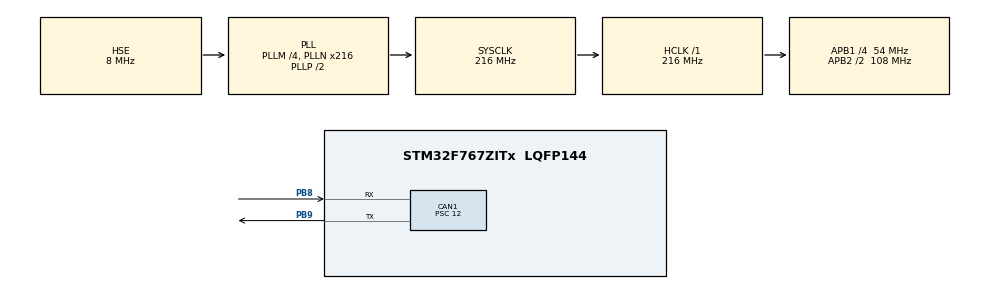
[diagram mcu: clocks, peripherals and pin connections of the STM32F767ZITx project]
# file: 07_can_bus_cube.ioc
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CAN1.BS1=CAN_BS1_15TQ
CAN1.BS2=CAN_BS2_2TQ
CAN1.CalculateBaudRate=250000
CAN1.CalculateTimeBit=4000
CAN1.CalculateTimeQuantum=222.22222222222223
CAN1.Mode=CAN_MODE_NORMAL
CAN1.Prescaler=12
CAN1.SJW=CAN_SJW_1TQ
Mcu.Family=STM32F7
Mcu.Name=STM32F767ZITx
Mcu.Package=LQFP144
NVIC.CAN1_RX0_IRQn=true\:0\:0\:false\:false\:true\:true\:true
NVIC.CAN1_RX1_IRQn=true\:0\:0\:false\:false\:true\:true\:true
NVIC.CAN1_SCE_IRQn=true\:0\:0\:false\:false\:true\:true\:true
NVIC.CAN1_TX_IRQn=true\:0\:0\:false\:false\:true\:true\:true
NVIC.PriorityGroup=NVIC_PRIORITYGROUP_4
NVIC.RCC_IRQn=true\:0\:0\:false\:false\:true\:true\:false
PB8.Mode=CAN_Activate
PB8.Signal=CAN1_RX
PB9.Mode=CAN_Activate
PB9.Signal=CAN1_TX
PH0/OSC_IN.Mode=HSE-External-Clock-Source
PH0/OSC_IN.Signal=RCC_OSC_IN
PH1/OSC_OUT.Mode=HSE-External-Clock-Source
PH1/OSC_OUT.Signal=RCC_OSC_OUT
ProjectManager.HeapSize=0x200
ProjectManager.StackSize=0x400
ProjectManager.TargetToolchain=STM32CubeIDE
RCC.AHBFreq_Value=216000000
RCC.APB1CLKDivider=RCC_HCLK_DIV4
RCC.APB1Freq_Value=54000000
RCC.APB1TimFreq_Value=108000000
RCC.APB2CLKDivider=RCC_HCLK_DIV2
RCC.APB2Freq_Value=108000000
RCC.APB2TimFreq_Value=216000000
RCC.CortexFreq_Value=216000000
RCC.EnbaleCSS=true
RCC.HCLKFreq_Value=216000000
RCC.HSE_VALUE=8000000
RCC.HSI_VALUE=16000000
RCC.LSE_VALUE=32768
RCC.PLLM=4
RCC.PLLN=216
RCC.PLLSourceVirtual=RCC_PLLSOURCE_HSE
RCC.SYSCLKFreq_VALUE=216000000
RCC.SYSCLKSource=RCC_SYSCLKSOURCE_PLLCLK
RCC.USBFreq_Value=216000000
RCC.VCOOutputFreq_Value=432000000
board=custom

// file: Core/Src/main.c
/* USER CODE BEGIN Header */
/**
  ******************************************************************************
  * @file           : main.c
  * @brief          : Main program body
  ******************************************************************************
  * @attention
  *
  * <h2><center>&copy; Copyright (c) 2021 STMicroelectronics.
  * All rights reserved.</center></h2>
  *
  * This software component is licensed by ST under BSD 3-Clause license,
  * the "License"; You may not use this file except in compliance with the
  * License. You may obtain a copy of the License at:
  *                        opensource.org/licenses/BSD-3-Clause
  *
  ******************************************************************************
  */
/* USER CODE END Header */
#include "main.h"

CAN_HandleTypeDef hcan1;

/* USER CODE BEGIN PV */

// TX and RX msg typedef

CAN_RxHeaderTypeDef RxHeader;
CAN_TxHeaderTypeDef TxHeader;

uint32_t err_counter = 0;
uint8_t TxData[8];
uint8_t RxData[8];

uint32_t TxMailBox;
uint32_t rx_counter =0;

/* USER CODE END PV */

void SystemClock_Config(void);
static void MX_GPIO_Init(void);
static void MX_CAN1_Init(void);
/* USER CODE BEGIN PFP */

void myCanFilterConfig(void);

/* USER CODE END PFP */

int main(void)
{

  /* MCU Configuration--------------------------------------------------------*/

  /* Reset of all peripherals, Initializes the Flash interface and the Systick. */
  HAL_Init();

  /* Configure the system clock */
  SystemClock_Config();

  /* Initialize all configured peripherals */
  MX_GPIO_Init();
  MX_CAN1_Init();
  /* USER CODE BEGIN 2 */

  HAL_CAN_Start(&hcan1);

  // Activate Notification

  HAL_CAN_ActivateNotification(&hcan1, CAN_IT_RX_FIFO0_MSG_PENDING);

  TxHeader.DLC = 1;
  TxHeader.IDE = CAN_ID_STD;
  TxHeader.RTR = CAN_RTR_DATA;

  TxHeader.StdId = 0x103;
  TxData[0] = 45;

  HAL_CAN_AddTxMessage(&hcan1, &TxHeader, TxData, &TxMailBox);

  /* USER CODE END 2 */

  /* Infinite loop */
  while (1)
  {

    /* USER CODE BEGIN 3 */
	  HAL_CAN_AddTxMessage(&hcan1, &TxHeader, TxData, &TxMailBox);
	  HAL_Delay(1000);
  }
  /* USER CODE END 3 */
}

void SystemClock_Config(void)
{
  RCC_OscInitTypeDef RCC_OscInitStruct = {0};
  RCC_ClkInitTypeDef RCC_ClkInitStruct = {0};

  /** Configure the main internal regulator output voltage
  */
  __HAL_RCC_PWR_CLK_ENABLE();
  __HAL_PWR_VOLTAGESCALING_CONFIG(PWR_REGULATOR_VOLTAGE_SCALE1);
  /** Initializes the RCC Oscillators according to the specified parameters
  * in the RCC_OscInitTypeDef structure.
  */
  RCC_OscInitStruct.OscillatorType = RCC_OSCILLATORTYPE_HSE;
  RCC_OscInitStruct.HSEState = RCC_HSE_BYPASS;
  RCC_OscInitStruct.PLL.PLLState = RCC_PLL_ON;
  RCC_OscInitStruct.PLL.PLLSource = RCC_PLLSOURCE_HSE;
  RCC_OscInitStruct.PLL.PLLM = 4;
  RCC_OscInitStruct.PLL.PLLN = 216;
  RCC_OscInitStruct.PLL.PLLP = RCC_PLLP_DIV2;
  RCC_OscInitStruct.PLL.PLLQ = 2;
  RCC_OscInitStruct.PLL.PLLR = 2;
  if (HAL_RCC_OscConfig(&RCC_OscInitStruct) != HAL_OK)
  {
    Error_Handler();
  }
  /** Activate the Over-Drive mode
  */
  if (HAL_PWREx_EnableOverDrive() != HAL_OK)
  {
    Error_Handler();
  }
  /** Initializes the CPU, AHB and APB buses clocks
  */
  RCC_ClkInitStruct.ClockType = RCC_CLOCKTYPE_HCLK|RCC_CLOCKTYPE_SYSCLK
                              |RCC_CLOCKTYPE_PCLK1|RCC_CLOCKTYPE_PCLK2;
  RCC_ClkInitStruct.SYSCLKSource = RCC_SYSCLKSOURCE_PLLCLK;
  RCC_ClkInitStruct.AHBCLKDivider = RCC_SYSCLK_DIV1;
  RCC_ClkInitStruct.APB1CLKDivider = RCC_HCLK_DIV4;
  RCC_ClkInitStruct.APB2CLKDivider = RCC_HCLK_DIV2;

  if (HAL_RCC_ClockConfig(&RCC_ClkInitStruct, FLASH_LATENCY_7) != HAL_OK)
  {
    Error_Handler();
  }
  /** Enables the Clock Security System
  */
  HAL_RCC_EnableCSS();
}

static void MX_CAN1_Init(void)
{

  hcan1.Instance = CAN1;
  hcan1.Init.Prescaler = 12;
  hcan1.Init.Mode = CAN_MODE_NORMAL;
  hcan1.Init.SyncJumpWidth = CAN_SJW_1TQ;
  hcan1.Init.TimeSeg1 = CAN_BS1_15TQ;
  hcan1.Init.TimeSeg2 = CAN_BS2_2TQ;
  hcan1.Init.TimeTriggeredMode = DISABLE;
  hcan1.Init.AutoBusOff = DISABLE;
  hcan1.Init.AutoWakeUp = DISABLE;
  hcan1.Init.AutoRetransmission = DISABLE;
  hcan1.Init.ReceiveFifoLocked = DISABLE;
  hcan1.Init.TransmitFifoPriority = DISABLE;
  if (HAL_CAN_Init(&hcan1) != HAL_OK)
  {
    Error_Handler();
  }
  /* USER CODE BEGIN CAN1_Init 2 */
  myCanFilterConfig();
  /* USER CODE END CAN1_Init 2 */

}

static void MX_GPIO_Init(void)
{

  /* GPIO Ports Clock Enable */
  __HAL_RCC_GPIOH_CLK_ENABLE();
  __HAL_RCC_GPIOB_CLK_ENABLE();

}

/* USER CODE BEGIN 4 */

void HAL_CAN_RxFifo0MsgPendingCallback(CAN_HandleTypeDef *hcan)
{

	HAL_CAN_GetRxMessage(&hcan1, CAN_RX_FIFO0, &RxHeader, RxData);
	rx_counter++;

}

void myCanFilterConfig(void){
	CAN_FilterTypeDef filterConfig;

	filterConfig.FilterBank = 13;
	filterConfig.FilterActivation = ENABLE;
	filterConfig.FilterFIFOAssignment = CAN_FILTER_FIFO0;
	filterConfig.FilterIdHigh = 0x0000;
	filterConfig.FilterIdLow = 0x0000;
	filterConfig.FilterMaskIdHigh = 0x0000;
	filterConfig.FilterMaskIdLow = 0x0000;
	filterConfig.FilterMode = CAN_FILTERMODE_IDMASK;

	filterConfig.FilterScale = CAN_FILTERSCALE_32BIT;

	HAL_StatusTypeDef  filacstatus = HAL_CAN_ConfigFilter(&hcan1, &filterConfig);
	if (filacstatus != HAL_OK)
	{
		Error_Handler();
	}
}
/* USER CODE END 4 */

void Error_Handler(void)
{
  __disable_irq();
  while (1)
  {
  }
}
